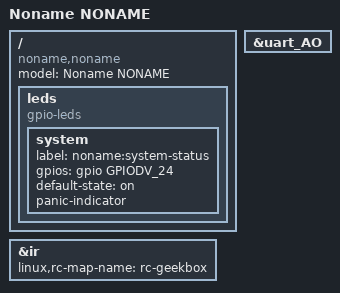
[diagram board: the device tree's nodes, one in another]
/*
 * Copyright (c) 2017 BayLibre, SAS.
 * Author: Neil Armstrong <narmstrong@baylibre.com>
 *
 * SPDX-License-Identifier: (GPL-2.0+ OR MIT)
 */

/dts-v1/;

#include <dt-bindings/input/input.h>

#include "meson-gxl-s905x-p212.dtsi"

/ {
	compatible = "noname,noname", "amlogic,s905x", "amlogic,meson-gxl";
	model = "Noname NONAME";

	leds {
		compatible = "gpio-leds";

		system {
			label = "noname:system-status";
			gpios = <&gpio GPIODV_24 GPIO_ACTIVE_HIGH>;
			default-state = "on";
			panic-indicator;
		};
	};
};

&ir {
	linux,rc-map-name = "rc-geekbox";
};

&uart_AO {
	status = "okay";
};
